# Analog_Pool_1 register map
Vendor: Texas Instruments
Peripheral module from a debugger description file (folder msp430).
Registers are 16-bit, read-write, reset 0x0 unless marked. A register's access mark holds for its fields unless they carry their own. Offsets are as the file gives them; lines under a group give offsets from that group; [hi:lo] are bit positions; {n}, {i} and the like mark numbered series; 'fields as' and 'values as' point back to an identical list; <NAME> marks a mode.

## Analog_Pool
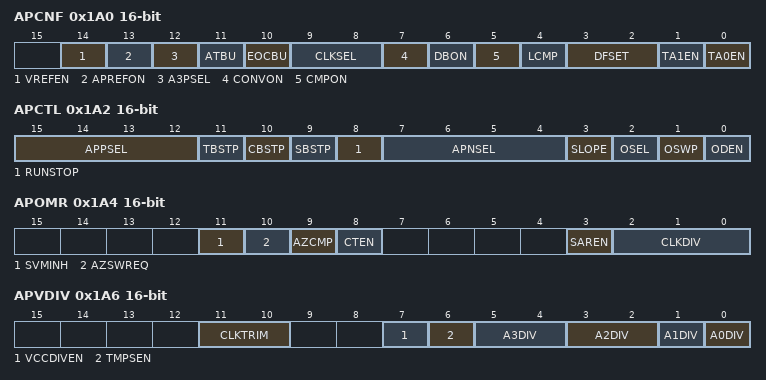
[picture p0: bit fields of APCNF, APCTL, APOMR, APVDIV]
0x1A0 APCNF — A-POOL Configuration Register
  [14] VREFEN — A-POOL Reference voltage pin enable
  [13] APREFON — A-POOL Internal voltage reference enable
  [12] A3PSEL — A-POOL Analog input A3 access Bit
  [11] ATBU — A-POOL Automatic update of conversion register
  [10] EOCBU — A-POOL Enable bit for loading conversion buffer
  [9:8] CLKSEL — A-POOL Conversion clock select Bit: 0
    0=A-POOL Conversion clock select: 0; 1=A-POOL Conversion clock select: 1; 2=A-POOL Conversion clock select: 2
  [7] CONVON — A-POOL Enable for converter's resistor ladder
  [6] DBON — A-POOL DAC buffer enable signal
  [5] CMPON — A-POOL Comparator enable
  [4] LCMP — A-POOL Latch comparator
  [3:2] DFSET — A-POOL Deglitch Filter Bit: 0
    {v}=A-POOL Deglitch Filter select: {v} (v=0..3)
  [1] TA1EN — A-POOL TimerA1 trigger enable
  [0] TA0EN — A-POOL TimerA0 trigger enable
0x1A2 APCTL — A-POOL Control Register 1
  [15:12] APPSEL — A-POOL Pos. Channel Input Select 0
    {v}=A-POOL V+ Terminal Input Select: Channel {v} (v=0..8)
  [11] TBSTP — A-POOL Timer based conversion stop enable for TimerA0
  [10] CBSTP — A-POOL Comparator based conversion stop enable
  [9] SBSTP — A-POOL Saturation based conversion stop enable
  [8] RUNSTOP — A-POOL Converter's Run/Stop bit
  [7:4] APNSEL — A-POOL Neg. Channel Input Select 0
    {v}=A-POOL V- terminal Input Select: Channel {v} (v=0..7)
  [3] SLOPE — A-POOL Slope select of converter
  [2] OSEL — A-POOL Output buffer select
  [1] OSWP — A-POOL Output swap
  [0] ODEN — A-POOL Output driver enable
0x1A4 APOMR — A-POOL Operation Mode Register 2
  [11] SVMINH — A-POOL Suppress the generation of an SVM interrupt event.
  [10] AZSWREQ — A-POOL SW request for Auto Zero Phase
  [9] AZCMP — A-POOL Clocked zero compensated long term comparison
  [8] CTEN — A-POOL Continuous time mode of comparator
  [3] SAREN — A-POOL SAR conversion enable
  [2:0] CLKDIV — A-POOL Prescaler Control Bit: 0
    0=A-POOL Prescaler Control 0 : /1; 1=A-POOL Prescaler Control 1 : /2; 2=A-POOL Prescaler Control 2 : /4; 3=A-POOL Prescaler Control 3 : /8; 4=A-POOL Prescaler Control 4 : /16; 5=A-POOL Prescaler Control 5 : /32
0x1A6 APVDIV — A-POOL Voltage Divider Register 3
  [11:10] CLKTRIM — A-POOL Clock trimming Bit : 0
    {v}=A-POOL Clock trimming: {v} (v=0..3)
  [7] VCCDIVEN — A-POOL VCC voltage divider enable
  [6] TMPSEN — A-POOL Temperature sensor enable
  [5:4] A3DIV — A-POOL Analog channel #3 voltage divider control Bit : 0
    {v}=A-POOL Analog channel #3 voltage divider control: {v} (v=0..3)
  [3:2] A2DIV — A-POOL Analog channel #2 voltage divider control Bit : 0
    {v}=A-POOL Analog channel #2 voltage divider control: {v} (v=0..3)
  [1] A1DIV — A-POOL Analog channel #1 voltage divider control
  [0] A0DIV — A-POOL Analog channel #0 voltage divider control
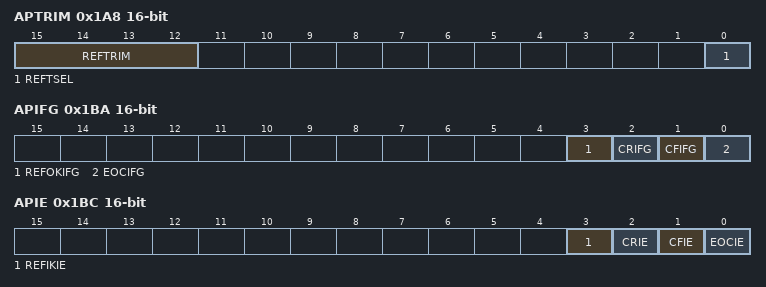
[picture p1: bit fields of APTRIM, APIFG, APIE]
0x1A8 APTRIM — A-POOL trimming register
  [15:12] REFTRIM — A-POOL Reference trimming bit: 0
    {v}=A-POOL Reference trimming: {v} (v=0..7)
  [0] REFTSEL — A-POOL Register bank used for the reference trimming
0x1B0 APINT access not given reset not defined — A-POOL Integer Conversion Register
0x1B2 APINTB access not given reset not defined — A-POOL Integer Conversion Buffer Register
0x1B4 APFRACT access not given reset not defined — A-POOL Fractional Conversion Register
0x1B6 APFRACTB access not given reset not defined — A-POOL Fractional Conversion Buffer Register
0x1BA APIFG — A-POOL Interrupt Flag Register
  [3] REFOKIFG — A-POOL Reference voltage ready interrupt flag
  [2] CRIFG — A-POOL Comparator rising edge interrupt flag
  [1] CFIFG — A-POOL Comparator falling edge interrupt flag
  [0] EOCIFG — A-POOL End of conversion interrupt flag
0x1BC APIE — A-POOL Interrupt Enable Register
  [3] REFIKIE — A-POOL Reference voltage ready interrupt enable
  [2] CRIE — A-POOL Comparator rising edge interrupt enable
  [1] CFIE — A-POOL Comparator falling edge interrupt enable
  [0] EOCIE — A-POOL End of conversion interrupt enable
0x1BE APIV access not given reset not defined — A-POOL Interrupt Vector Word
